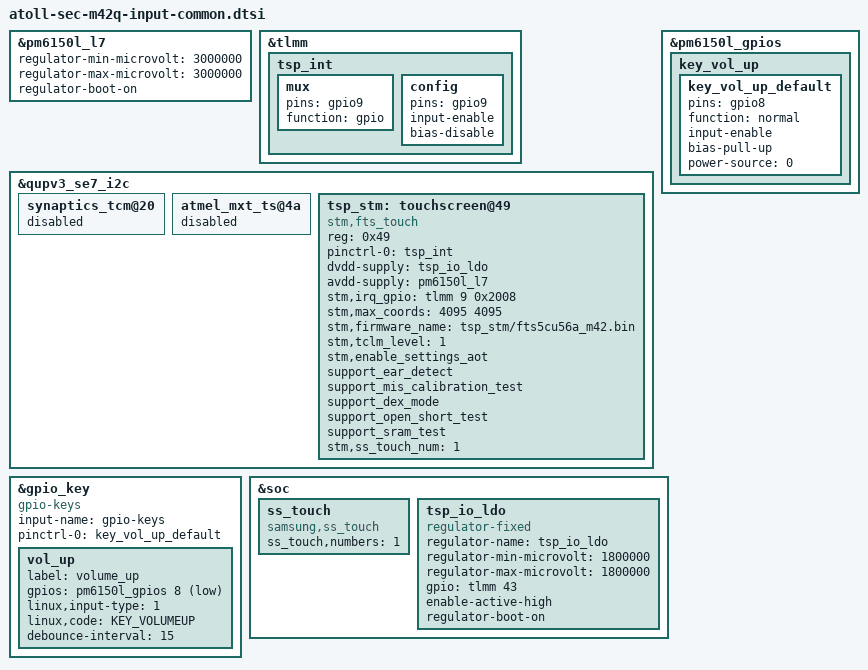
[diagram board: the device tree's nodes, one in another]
/* Copyright (c) 2016-2017, The Linux Foundation. All rights reserved.
 *
 * This program is free software; you can redistribute it and/or modify
 * it under the terms of the GNU General Public License version 2 and
 * only version 2 as published by the Free Software Foundation.
 *
 * This program is distributed in the hope that it will be useful,
 * but WITHOUT ANY WARRANTY; without even the implied warranty of
 * MERCHANTABILITY or FITNESS FOR A PARTICULAR PURPOSE.  See the
 * GNU General Public License for more details.
 */

#include <dt-bindings/input/input.h>
#include <dt-bindings/msm/msm-bus-ids.h>

&pm6150l_l7 {
	regulator-min-microvolt = <3000000>;
	regulator-max-microvolt = <3000000>;
	regulator-boot-on;
};

&tlmm {
	tsp_int: tsp_int {
		mux {
			pins = "gpio9";
			function = "gpio";
		};
		
		config {
			pins = "gpio9";
			input-enable;
			bias-disable;
		};
	};
};

&qupv3_se7_i2c {
	status = "ok";
	synaptics_tcm@20 {
		status = "disabled";
	};
	atmel_mxt_ts@4a {
		status = "disabled";
	};

	tsp_stm: touchscreen@49 {
		status = "ok";
		compatible = "stm,fts_touch";
		reg = <0x49>;
		pinctrl-names = "default";
		pinctrl-0 = <&tsp_int>;
		dvdd-supply = <&tsp_io_ldo>;
		avdd-supply = <&pm6150l_l7>;
		stm,irq_gpio = <&tlmm 9 0x2008>;
		stm,max_coords = <4095 4095>;
		stm,firmware_name = "tsp_stm/fts5cu56a_m42.bin";
		stm,tclm_level = <1>;
		/* stm,afe_base = <0x7>; */
		stm,enable_settings_aot;
		support_ear_detect;
		support_mis_calibration_test;
		support_dex_mode;
		support_open_short_test;
		support_sram_test;
		stm,ss_touch_num = <1>;
	};
};

/delete-node/&key_vol_up_default;
&pm6150l_gpios {
	key_vol_up {
		key_vol_up_default: key_vol_up_default {
			pins = "gpio8";
			function = "normal";
			input-enable;
			bias-pull-up;
			power-source = <0>;
		};
	};
};

/delete-node/&gpio_key;
&gpio_key {
	status = "okay";
	compatible = "gpio-keys";
	input-name = "gpio-keys";

	pinctrl-names = "default";
	pinctrl-0 = <&key_vol_up_default>;

	vol_up {
		label = "volume_up";
		gpios = <&pm6150l_gpios 8 0x1>;
		linux,input-type = <1>;
		linux,code = <KEY_VOLUMEUP>;
		debounce-interval = <15>;
	};
};

&soc {
	ss_touch {
		compatible = "samsung,ss_touch";
		ss_touch,numbers = <1>;
	};

	tsp_io_ldo: tsp_io_ldo {
		compatible = "regulator-fixed";
		regulator-name = "tsp_io_ldo";
		regulator-min-microvolt = <1800000>;
		regulator-max-microvolt = <1800000>;
		gpio = <&tlmm 43 0>;
		enable-active-high;
		regulator-boot-on;
	};
};
